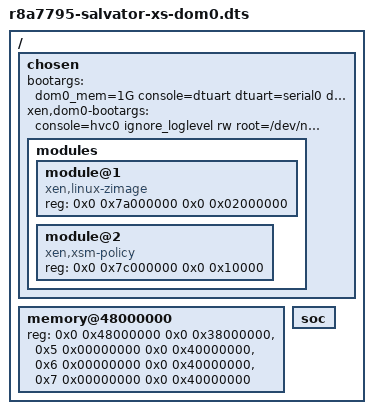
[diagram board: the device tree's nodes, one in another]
/*
 * Device Tree Source for the Salvator-XS board
 * running XEN hypervisor
 *
 * Copyright (C) 2015 Renesas Electronics Corp.
 *
 * This file is licensed under the terms of the GNU General Public License
 * version 2.  This program is licensed "as is" without any warranty of any
 * kind, whether express or implied.
 */

#include "r8a7795-salvator-xs.dts"

/ {
	chosen {
		bootargs = "dom0_mem=1G console=dtuart dtuart=serial0 dom0_max_vcpus=4 bootscrub=0 flask_enforcing=1 loglvl=all cpufreq=none";
		xen,dom0-bootargs = "console=hvc0 ignore_loglevel rw root=/dev/nfs nfsroot=192.168.1.100:/srv/rcar-root,nfsvers=3 ip=192.168.1.10 cma=384M";
		/delete-property/stdout-path;
		modules {
			#address-cells = <2>;
			#size-cells = <2>;
			module@1 {
				compatible = "xen,linux-zimage", "xen,multiboot-module";
				reg = <0x0 0x7a000000 0x0 0x02000000>;
			};
			module@2 {
				compatible = "xen,xsm-policy", "xen,multiboot-module";
				reg = <0x0 0x7c000000 0x0 0x10000>;
			};
		};
	};

	memory@48000000 {
		device_type = "memory";
		/* first 128MB is reserved for secure area. */
		reg = <0x0 0x48000000 0x0 0x38000000>,
			  <0x5 0x00000000 0x0 0x40000000>,
			  <0x6 0x00000000 0x0 0x40000000>,
			  <0x7 0x00000000 0x0 0x40000000>;
	};

	/delete-node/memory@500000000;
	/delete-node/memory@600000000;
	/delete-node/memory@700000000;
	/delete-node/reserved-memory;

	/delete-node/mmngr;
	/delete-node/mmngrbuf;

	/*
	 * When creating DT for the guest domain Xen inserts only dummy CPU nodes.
	 * And the number of these inserted CPU nodes is equal to the number of
	 * vCPUs assigned to this domain. All CPU properties which original DT has,
	 * such as OPP, clock, regulator, etc are not passed to the guest’s DT.
	 *
	 * Example of guest vCPU node:
	 *
	 * cpu@0 {
	 *     device_type = "cpu";
	 *     compatible = "arm,armv8";
	 *     enable-method = "psci";
	 *     reg = <0x0>;
	 * };
	 *
	 * This results in the fact that all features expecting a57_x or a53_x
	 * CPU nodes to be present get broken. This is why we have to explicitly
	 * remove the following.
	 */
	soc {
		/delete-node/thermal-zones;
		/delete-node/pmu_a57;
		/delete-node/pmu_a53;
	};
};

/delete-node/&adsp;

